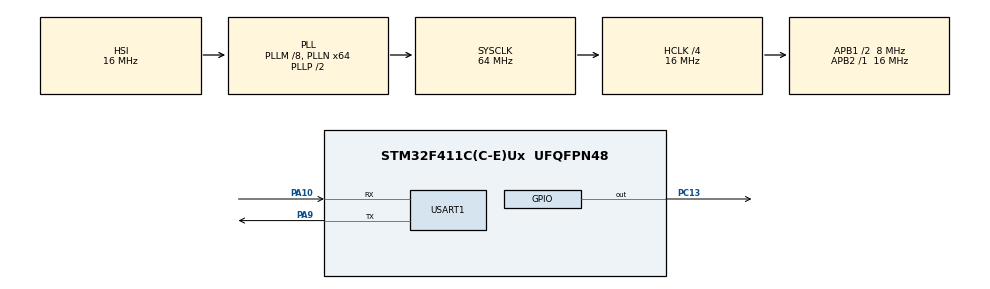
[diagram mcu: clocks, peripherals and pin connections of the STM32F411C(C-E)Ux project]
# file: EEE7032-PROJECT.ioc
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FREERTOS.Tasks01=defaultTask,0,128,StartDefaultTask,Default,NULL,Dynamic,NULL,NULL
FREERTOS.configUSE_TICKLESS_IDLE=1
Mcu.Family=STM32F4
Mcu.Name=STM32F411C(C-E)Ux
Mcu.Package=UFQFPN48
NVIC.PriorityGroup=NVIC_PRIORITYGROUP_4
NVIC.TIM5_IRQn=true\:15\:0\:false\:false\:true\:false\:false\:true\:true
NVIC.TimeBase=TIM5_IRQn
NVIC.TimeBaseIP=TIM5
PA10.Mode=Asynchronous
PA10.Signal=USART1_RX
PA13.Mode=Serial_Wire
PA13.Signal=SYS_JTMS-SWDIO
PA14.Mode=Serial_Wire
PA14.Signal=SYS_JTCK-SWCLK
PA9.Mode=Asynchronous
PA9.Signal=USART1_TX
PC13-ANTI_TAMP.Signal=GPIO_Output
PH0\ -\ OSC_IN.Mode=HSE-External-Oscillator
PH0\ -\ OSC_IN.Signal=RCC_OSC_IN
PH1\ -\ OSC_OUT.Mode=HSE-External-Oscillator
PH1\ -\ OSC_OUT.Signal=RCC_OSC_OUT
ProjectManager.HeapSize=0x200
ProjectManager.StackSize=0x400
ProjectManager.TargetToolchain=STM32CubeIDE
RCC.48MHZClocksFreq_Value=32000000
RCC.AHBCLKDivider=RCC_SYSCLK_DIV4
RCC.AHBFreq_Value=16000000
RCC.APB1CLKDivider=RCC_HCLK_DIV2
RCC.APB1Freq_Value=8000000
RCC.APB1TimFreq_Value=16000000
RCC.APB2Freq_Value=16000000
RCC.APB2TimFreq_Value=16000000
RCC.CortexFreq_Value=16000000
RCC.HCLKFreq_Value=16000000
RCC.HSE_VALUE=25000000
RCC.HSI_VALUE=16000000
RCC.LSE_VALUE=32768
RCC.PLLM=8
RCC.PLLN=64
RCC.SYSCLKFreq_VALUE=64000000
RCC.SYSCLKSource=RCC_SYSCLKSOURCE_PLLCLK
RCC.VCOOutputFreq_Value=128000000
TIM2.Period=65535
TIM2.Prescaler=99
USART1.VirtualMode=VM_ASYNC
VP_FREERTOS_VS_CMSIS_V1.Mode=CMSIS_V1
VP_SYS_VS_tim5.Mode=TIM5
VP_TIM2_VS_ClockSourceINT.Mode=Internal
board=custom

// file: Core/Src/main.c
/* USER CODE BEGIN Header */
/**
  ******************************************************************************
  * @file           : main.c
  * @brief          : Main program body
  ******************************************************************************
  * @attention
  *
  * Copyright (c) 2026 STMicroelectronics.
  * All rights reserved.
  *
  * This software is licensed under terms that can be found in the LICENSE file
  * in the root directory of this software component.
  * If no LICENSE file comes with this software, it is provided AS-IS.
  *
  ******************************************************************************
  */
/* USER CODE END Header */
#include "main.h"
#include "cmsis_os.h"

/* USER CODE BEGIN PD */
#define TARGET_TASK_COUNT  2  /* S1 ve S2 senaryosu için 2, sonra 8 yapacağız */
/* USER CODE END PD */

TIM_HandleTypeDef htim2;

UART_HandleTypeDef huart1;

osThreadId defaultTaskHandle;
/* USER CODE BEGIN PV */
// FreeRTOSConfig.h içindeki makroların kullanacağı gerçek değişken tanımlamaları:
volatile uint32_t switch_start_time = 0;
volatile uint32_t switch_end_time = 0;
volatile uint32_t context_switch_latency_us = 0;
volatile uint32_t max_latency = 0;

// SWV üzerinden çıktı almak için kullandığımız fonksiyon:
int __io_putchar(int ch) {
    ITM_SendChar(ch);
    return ch;
}
/* USER CODE END PV */

void SystemClock_Config(void);
static void MX_GPIO_Init(void);
static void MX_TIM2_Init(void);
static void MX_USART1_UART_Init(void);
void StartDefaultTask(void const * argument);

/* USER CODE BEGIN 0 */
void vDummyTask(void *pvParameters) {
    uint32_t task_id = (uint32_t)pvParameters;
    (void)task_id;

    for(;;) {
        // Task 0 çalışırken LED'in durumunu değiştirerek göz kırpmasını sağlayalım
        if(task_id == 0) {
            HAL_GPIO_TogglePin(GPIOC, GPIO_PIN_13);
        }

        volatile uint32_t count = 0;
        for(count = 0; count < 500; count++);

        // Görsel olarak flaşör etkisini yakalamak için gecikmeyi 200 ms yapalım
        vTaskDelay(pdMS_TO_TICKS(200));
    }
}
/* USER CODE END 0 */

int main(void)
{

  /* MCU Configuration--------------------------------------------------------*/

  /* Reset of all peripherals, Initializes the Flash interface and the Systick. */
  HAL_Init();

  /* Configure the system clock */
  SystemClock_Config();

  /* Initialize all configured peripherals */
  MX_GPIO_Init();
  MX_TIM2_Init();
  MX_USART1_UART_Init();
  /* USER CODE BEGIN 2 */
    HAL_TIM_Base_Start(&htim2); // Ölçüm timer'ını başlatıyoruz

    printf("\r\n--- FreeRTOS Overhead & Latency Test Started ---\r\n");
    printf("Active Task Count: %d\r\n", TARGET_TASK_COUNT);
  /* USER CODE END 2 */

  /* Create the thread(s) */
  /* definition and creation of defaultTask */
  osThreadDef(defaultTask, StartDefaultTask, osPriorityNormal, 0, 128);
  defaultTaskHandle = osThreadCreate(osThread(defaultTask), NULL);

  /* Start scheduler */
  osKernelStart();
  /* We should never get here as control is now taken by the scheduler */
  /* Infinite loop */
  while (1)
  {

  }
}

void SystemClock_Config(void)
{
  RCC_OscInitTypeDef RCC_OscInitStruct = {0};
  RCC_ClkInitTypeDef RCC_ClkInitStruct = {0};

  /** Configure the main internal regulator output voltage
  */
  __HAL_RCC_PWR_CLK_ENABLE();
  __HAL_PWR_VOLTAGESCALING_CONFIG(PWR_REGULATOR_VOLTAGE_SCALE1);

  /** Initializes the RCC Oscillators according to the specified parameters
  * in the RCC_OscInitTypeDef structure.
  */
  RCC_OscInitStruct.OscillatorType = RCC_OSCILLATORTYPE_HSI;
  RCC_OscInitStruct.HSIState = RCC_HSI_ON;
  RCC_OscInitStruct.HSICalibrationValue = RCC_HSICALIBRATION_DEFAULT;
  RCC_OscInitStruct.PLL.PLLState = RCC_PLL_ON;
  RCC_OscInitStruct.PLL.PLLSource = RCC_PLLSOURCE_HSI;
  RCC_OscInitStruct.PLL.PLLM = 8;
  RCC_OscInitStruct.PLL.PLLN = 64;
  RCC_OscInitStruct.PLL.PLLP = RCC_PLLP_DIV2;
  RCC_OscInitStruct.PLL.PLLQ = 4;
  if (HAL_RCC_OscConfig(&RCC_OscInitStruct) != HAL_OK)
  {
    Error_Handler();
  }

  /** Initializes the CPU, AHB and APB buses clocks
  */
  RCC_ClkInitStruct.ClockType = RCC_CLOCKTYPE_HCLK|RCC_CLOCKTYPE_SYSCLK
                              |RCC_CLOCKTYPE_PCLK1|RCC_CLOCKTYPE_PCLK2;
  RCC_ClkInitStruct.SYSCLKSource = RCC_SYSCLKSOURCE_PLLCLK;
  RCC_ClkInitStruct.AHBCLKDivider = RCC_SYSCLK_DIV4;
  RCC_ClkInitStruct.APB1CLKDivider = RCC_HCLK_DIV2;
  RCC_ClkInitStruct.APB2CLKDivider = RCC_HCLK_DIV1;

  if (HAL_RCC_ClockConfig(&RCC_ClkInitStruct, FLASH_LATENCY_0) != HAL_OK)
  {
    Error_Handler();
  }
}

static void MX_TIM2_Init(void)
{

  TIM_ClockConfigTypeDef sClockSourceConfig = {0};
  TIM_MasterConfigTypeDef sMasterConfig = {0};

  htim2.Instance = TIM2;
  htim2.Init.Prescaler = 99;
  htim2.Init.CounterMode = TIM_COUNTERMODE_UP;
  htim2.Init.Period = 65535;
  htim2.Init.ClockDivision = TIM_CLOCKDIVISION_DIV1;
  htim2.Init.AutoReloadPreload = TIM_AUTORELOAD_PRELOAD_DISABLE;
  if (HAL_TIM_Base_Init(&htim2) != HAL_OK)
  {
    Error_Handler();
  }
  sClockSourceConfig.ClockSource = TIM_CLOCKSOURCE_INTERNAL;
  if (HAL_TIM_ConfigClockSource(&htim2, &sClockSourceConfig) != HAL_OK)
  {
    Error_Handler();
  }
  sMasterConfig.MasterOutputTrigger = TIM_TRGO_RESET;
  sMasterConfig.MasterSlaveMode = TIM_MASTERSLAVEMODE_DISABLE;
  if (HAL_TIMEx_MasterConfigSynchronization(&htim2, &sMasterConfig) != HAL_OK)
  {
    Error_Handler();
  }

}

static void MX_USART1_UART_Init(void)
{

  huart1.Instance = USART1;
  huart1.Init.BaudRate = 115200;
  huart1.Init.WordLength = UART_WORDLENGTH_8B;
  huart1.Init.StopBits = UART_STOPBITS_1;
  huart1.Init.Parity = UART_PARITY_NONE;
  huart1.Init.Mode = UART_MODE_TX_RX;
  huart1.Init.HwFlowCtl = UART_HWCONTROL_NONE;
  huart1.Init.OverSampling = UART_OVERSAMPLING_16;
  if (HAL_UART_Init(&huart1) != HAL_OK)
  {
    Error_Handler();
  }

}

static void MX_GPIO_Init(void)
{
  GPIO_InitTypeDef GPIO_InitStruct = {0};

  /* GPIO Ports Clock Enable */
  __HAL_RCC_GPIOC_CLK_ENABLE();
  __HAL_RCC_GPIOH_CLK_ENABLE();
  __HAL_RCC_GPIOA_CLK_ENABLE();

  /*Configure GPIO pin Output Level */
  HAL_GPIO_WritePin(GPIOC, GPIO_PIN_13, GPIO_PIN_RESET);

  /*Configure GPIO pin : PC13 */
  GPIO_InitStruct.Pin = GPIO_PIN_13;
  GPIO_InitStruct.Mode = GPIO_MODE_OUTPUT_PP;
  GPIO_InitStruct.Pull = GPIO_NOPULL;
  GPIO_InitStruct.Speed = GPIO_SPEED_FREQ_LOW;
  HAL_GPIO_Init(GPIOC, &GPIO_InitStruct);

}

/* USER CODE BEGIN 4 */
void trace_context_switch_calculated(void) {
    if (switch_end_time >= switch_start_time) {
        context_switch_latency_us = switch_end_time - switch_start_time;

        // Akademik Peak/Worst-Case Filtresi
        if (context_switch_latency_us > max_latency) {
            max_latency = context_switch_latency_us;
        }
    }
}
/* USER CODE END 4 */

void StartDefaultTask(void const * argument)
{
  /* USER CODE BEGIN 5 */

  // Ana yönetim görevi (defaultTask) üzerinden test tasklarımızı güvenle yaratıyoruz:
  for(uint32_t i = 0; i < TARGET_TASK_COUNT; i++) {
      xTaskCreate(vDummyTask, "DummyTask", configMINIMAL_STACK_SIZE, (void*)i, 1, NULL);
  }

  /* Infinite loop */
  for(;;)
  {
    // defaultTask artık sadece arka planda bekleyecek ve testleri bozmayacak
    osDelay(1000);
  }
  /* USER CODE END 5 */
}

void HAL_TIM_PeriodElapsedCallback(TIM_HandleTypeDef *htim)
{
  if (htim->Instance == TIM5) {
    HAL_IncTick();
  }
}

void Error_Handler(void)
{
  __disable_irq();
  while (1)
  {
  }
}

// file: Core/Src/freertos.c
/* USER CODE BEGIN Header */
/**
  ******************************************************************************
  * File Name          : freertos.c
  * Description        : Code for freertos applications
  ******************************************************************************
  * @attention
  *
  * Copyright (c) 2026 STMicroelectronics.
  * All rights reserved.
  *
  * This software is licensed under terms that can be found in the LICENSE file
  * in the root directory of this software component.
  * If no LICENSE file comes with this software, it is provided AS-IS.
  *
  ******************************************************************************
  */
/* USER CODE END Header */

#include "FreeRTOS.h"
#include "task.h"
#include "main.h"

/* GetIdleTaskMemory prototype (linked to static allocation support) */
void vApplicationGetIdleTaskMemory( StaticTask_t **ppxIdleTaskTCBBuffer, StackType_t **ppxIdleTaskStackBuffer, uint32_t *pulIdleTaskStackSize );

/* USER CODE BEGIN PREPOSTSLEEP */
__weak void PreSleepProcessing(uint32_t ulExpectedIdleTime)
{
/* place for user code */
}

__weak void PostSleepProcessing(uint32_t ulExpectedIdleTime)
{
/* place for user code */
}
/* USER CODE END PREPOSTSLEEP */

/* USER CODE BEGIN GET_IDLE_TASK_MEMORY */
static StaticTask_t xIdleTaskTCBBuffer;
static StackType_t xIdleStack[configMINIMAL_STACK_SIZE];

void vApplicationGetIdleTaskMemory( StaticTask_t **ppxIdleTaskTCBBuffer, StackType_t **ppxIdleTaskStackBuffer, uint32_t *pulIdleTaskStackSize )
{
  *ppxIdleTaskTCBBuffer = &xIdleTaskTCBBuffer;
  *ppxIdleTaskStackBuffer = &xIdleStack[0];
  *pulIdleTaskStackSize = configMINIMAL_STACK_SIZE;
  /* place for user code */
}
/* USER CODE END GET_IDLE_TASK_MEMORY */
